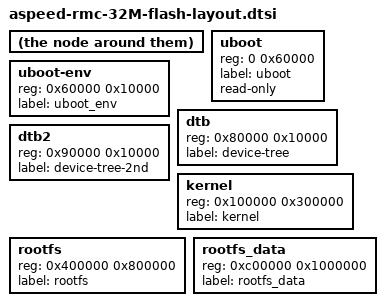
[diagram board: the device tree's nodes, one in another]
/* This file is the label for the bmc primary flash and its partitions */
				#address-cells = < 1 >;
				#size-cells = < 1 >;
				uboot {
					reg = < 0 0x60000 >;
					label = "uboot";
					read-only;
				};
				uboot-env {
					reg = < 0x60000 0x10000 >;
					label = "uboot_env";
				};
				dtb {
					reg = < 0x80000 0x10000 >;
					label = "device-tree";
				};
				dtb2 {
					reg = < 0x90000 0x10000 >;
					label = "device-tree-2nd";
				};
				kernel  {
					reg = < 0x100000 0x300000 >;
					label = "kernel";
				};
				rootfs {
					reg = < 0x400000 0x800000 >;
					label = "rootfs";
				};
				rootfs_data  {
					reg = < 0xc00000 0x1000000 >;
					label = "rootfs_data";
				};
